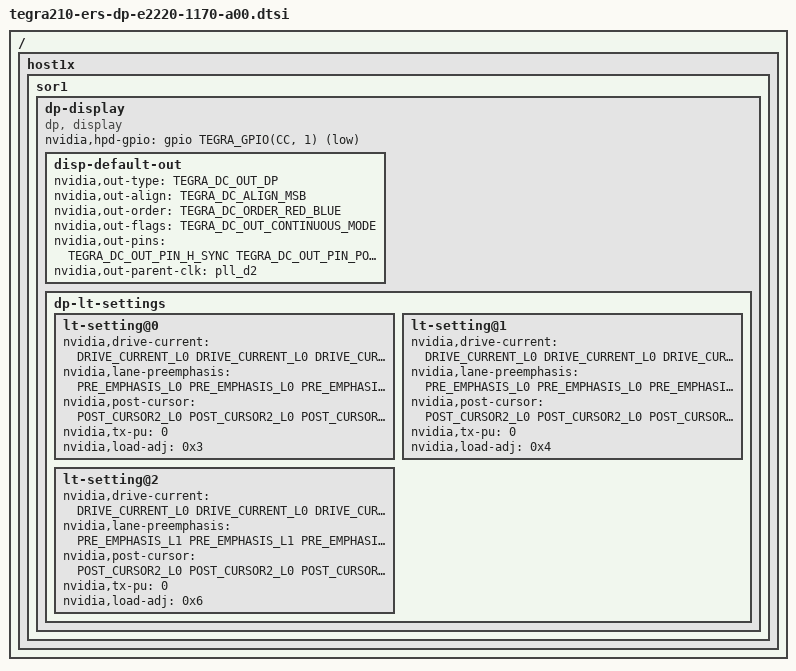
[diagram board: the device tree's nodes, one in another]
/*
 * arch/arm/boot/dts/tegra210-platforms/tegra210-ers-dp-e2220-1170-a00.dtsi
 *
 * Copyright (c) 2014-2015, NVIDIA CORPORATION.  All rights reserved.
 *
 * This program is free software; you can redistribute it and/or modify
 * it under the terms of the GNU General Public License as published by
 * the Free Software Foundation; either version 2 of the License, or
 * (at your option) any later version.
 *
 * This program is distributed in the hope that it will be useful, but WITHOUT
 * ANY WARRANTY; without even the implied warranty of MERCHANTABILITY or
 * FITNESS FOR A PARTICULAR PURPOSE.  See the GNU General Public License for
 * more details.
 *
 * You should have received a copy of the GNU General Public License along
 * with this program; if not, write to the Free Software Foundation, Inc.,
 * 51 Franklin Street, Fifth Floor, Boston, MA  02110-1301, USA.
 */
#include <dt-bindings/display/tegra-dc.h>
#include <dt-bindings/display/tegra-panel.h>

/ {
	host1x {
		sor1 {
			dp-display {
				status = "okay";
				compatible = "dp, display";
				nvidia,hpd-gpio = <&gpio TEGRA_GPIO(CC, 1) 1>; /* PN7 */
				disp-default-out {
					nvidia,out-type = <TEGRA_DC_OUT_DP>;
					nvidia,out-align = <TEGRA_DC_ALIGN_MSB>;
					nvidia,out-order = <TEGRA_DC_ORDER_RED_BLUE>;
					nvidia,out-flags = <TEGRA_DC_OUT_CONTINUOUS_MODE>;
					nvidia,out-pins = <TEGRA_DC_OUT_PIN_H_SYNC TEGRA_DC_OUT_PIN_POL_LOW
							   TEGRA_DC_OUT_PIN_V_SYNC TEGRA_DC_OUT_PIN_POL_LOW
							   TEGRA_DC_OUT_PIN_PIXEL_CLOCK TEGRA_DC_OUT_PIN_POL_LOW
							   TEGRA_DC_OUT_PIN_DATA_ENABLE TEGRA_DC_OUT_PIN_POL_HIGH>;
					nvidia,out-parent-clk = "pll_d2";
				};
				dp-lt-settings {
					lt-setting@0 {
						nvidia,drive-current = <DRIVE_CURRENT_L0 DRIVE_CURRENT_L0 DRIVE_CURRENT_L0 DRIVE_CURRENT_L0>;
						nvidia,lane-preemphasis = <PRE_EMPHASIS_L0 PRE_EMPHASIS_L0 PRE_EMPHASIS_L0 PRE_EMPHASIS_L0>;
						nvidia,post-cursor = <POST_CURSOR2_L0 POST_CURSOR2_L0 POST_CURSOR2_L0 POST_CURSOR2_L0>;
						nvidia,tx-pu = <0>;
						nvidia,load-adj = <0x3>;
					};
					lt-setting@1 {
						nvidia,drive-current = <DRIVE_CURRENT_L0 DRIVE_CURRENT_L0 DRIVE_CURRENT_L0 DRIVE_CURRENT_L0>;
						nvidia,lane-preemphasis = <PRE_EMPHASIS_L0 PRE_EMPHASIS_L0 PRE_EMPHASIS_L0 PRE_EMPHASIS_L0>;
						nvidia,post-cursor = <POST_CURSOR2_L0 POST_CURSOR2_L0 POST_CURSOR2_L0 POST_CURSOR2_L0>;
						nvidia,tx-pu = <0>;
						nvidia,load-adj = <0x4>;
					};
					lt-setting@2 {
						nvidia,drive-current = <DRIVE_CURRENT_L0 DRIVE_CURRENT_L0 DRIVE_CURRENT_L0 DRIVE_CURRENT_L0>;
						nvidia,lane-preemphasis = <PRE_EMPHASIS_L1 PRE_EMPHASIS_L1 PRE_EMPHASIS_L1 PRE_EMPHASIS_L1>;
						nvidia,post-cursor = <POST_CURSOR2_L0 POST_CURSOR2_L0 POST_CURSOR2_L0 POST_CURSOR2_L0>;
						nvidia,tx-pu = <0>;
						nvidia,load-adj = <0x6>;
					};
				};
			};
		};
	};
};
